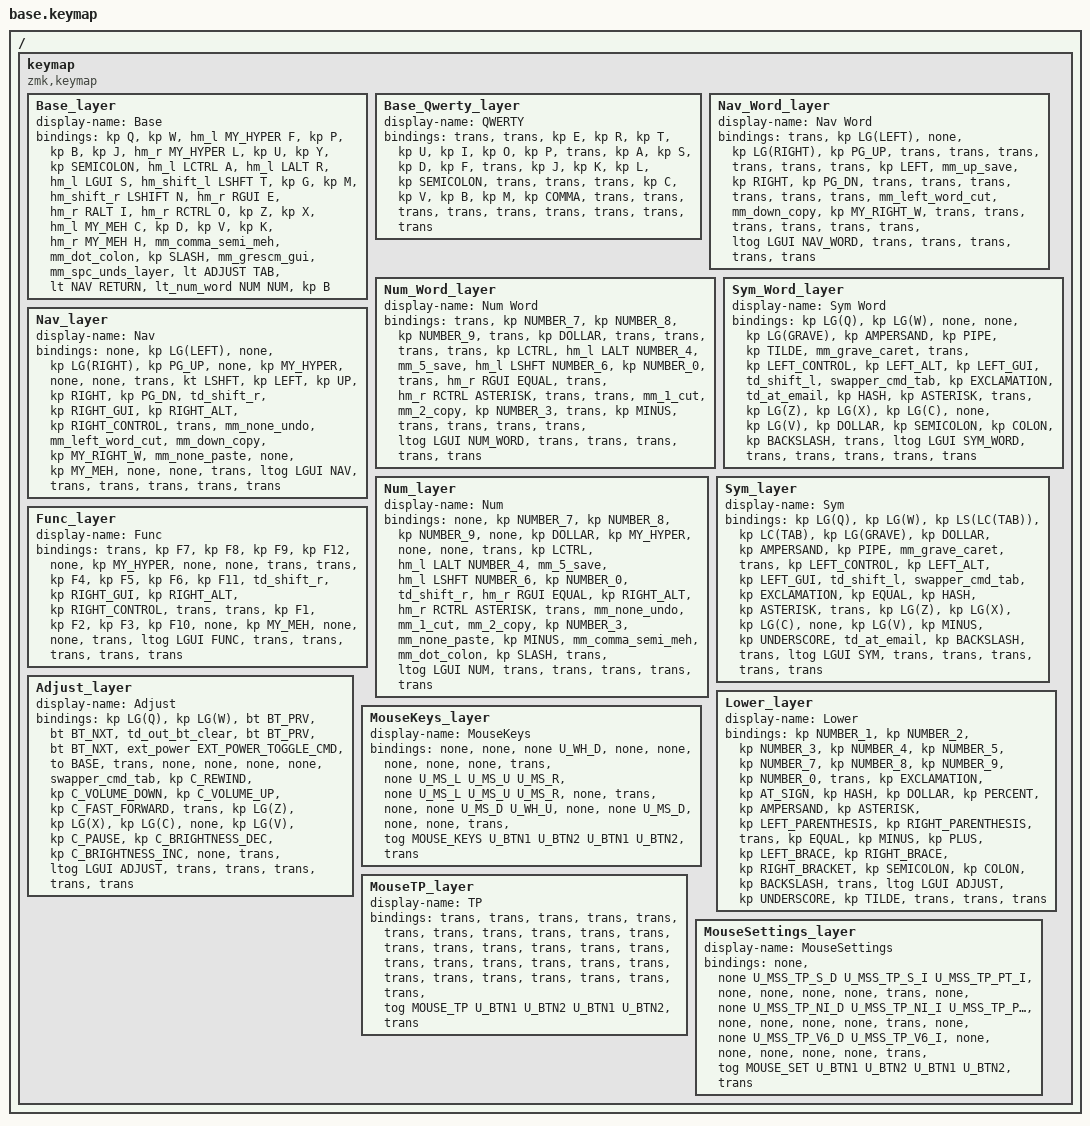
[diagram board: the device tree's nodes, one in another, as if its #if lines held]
/*
 * Copyright (c) 2020 The ZMK Contributors
 *
 * SPDX-License-Identifier: MIT
 */

// Define layer numbers
#define BASE 0
#define BASE_QWERTY 1
#define NAV_WORD 2
#define NUM_WORD 3
#define SYM_WORD 4
#define NAV 5
#define NUM 6
#define SYM 7
#define FUNC 8
#define ADJUST 9
#define LOWER 10
#define MOUSE_KEYS 11
#define MOUSE_TP 12
#define MOUSE_SET 13


// ZMK includes
#include <behaviors.dtsi>
#include <dt-bindings/zmk/keys.h>
#include <dt-bindings/zmk/bt.h>
#include <dt-bindings/zmk/rgb.h>
#include <dt-bindings/zmk/ext_power.h>

#ifdef HAS_MOUSE_KEYS
#include <dt-bindings/zmk/mouse.h>
#endif

#ifdef HAS_PS2
#include <dt-bindings/zmk/mouse_settings.h>
#endif


// Personal includes
#include "includes/custom_keycodes.dtsi"
#include "includes/settings.dtsi"
//#include "includes/settings_pd.dtsi"
#include "includes/conditional_layers.dtsi"
#include "includes/macros.dtsi"
#include "includes/combos.dtsi"
#include "includes/behaviours_homerow_mods.dtsi"
#include "includes/behaviours_mod_morph.dtsi"
#include "includes/behaviours_other.dtsi"

// Enable Mouse Keys

#ifdef HAS_MOUSE_KEYS
#include "includes/mouse_keys.dtsi"
#endif


/ {

  keymap {
    compatible = "zmk,keymap";

    Base_layer {
      display-name = "Base";
      bindings = <
// ┬────────────────────────┬────────────────────────┬────────────────────────┬────────────────────────┬────────────────────────╮    ┬────────────────────────┬────────────────────────┬───────────────────────┬─────────────────────
     &kp Q                    &kp W                    &hm_l MY_HYPER F         &kp P                    &kp B                         &kp J                    &hm_r MY_HYPER L         &kp U                    &kp Y         &kp SEMICOLON
// ┼────────────────────────┼────────────────────────┼────────────────────────┼────────────────────────┼────────────────────────┤    ┼────────────────────────┼────────────────────────┼───────────────────────┼────────────────────────┼────────────────────────┤
     &hm_l LCTRL A            &hm_l LALT R             &hm_l LGUI S             &hm_shift_l LSHFT T      &kp G                         &kp M                   &hm_shift_r LSHIFT N      &hm_r RGUI E             &hm_r RALT I             &hm_r RCTRL O
// ┼────────────────────────┼────────────────────────┼────────────────────────┼────────────────────────┼────────────────────────┤    ┼────────────────────────┼────────────────────────┼───────────────────────┼────────────────────────┼────────────────────────┤
     &kp Z                    &kp X                    &hm_l MY_MEH C           &kp D                    &kp V                         &kp K                   &hm_r MY_MEH H           &mm_comma_semi_meh       &mm_dot_colon            &kp SLASH
// ╰────────────────────────┴────────────────────────┴────────────────────────┴────────────────────────┼────────────────────────┼    ┼────────────────────────┼────────────────────────┼───────────────────────┼────────────────────────┼────────────────────────╯
                                                       &mm_grescm_gui           &mm_spc_unds_layer       &lt ADJUST TAB                &lt NAV RETURN           &lt_num_word NUM NUM        &kp B
//                                                   ╰────────────────────────┴────────────────────────┴────────────────────────╯    ╰────────────────────────┴────────────────────────┴────────────────────────╯

      >;
     //  sensor-bindings = <&inc_dec_kp C_VOL_DN C_VOL_UP &inc_dec_kp C_PREV C_NEXT>;
    };

    Base_Qwerty_layer {
      display-name = "QWERTY";
      bindings = <
// ┬────────────────────────┬────────────────────────┬────────────────────────┬────────────────────────┬────────────────────────╮    ┬────────────────────────┬────────────────────────┬────────────────────────┬────────────────────────┬────────────────────────╮
     &trans                   &trans                   &kp E                    &kp R                    &kp T                         &kp U                    &kp I                    &kp O                    &kp P                     &trans
// ┼────────────────────────┼────────────────────────┼────────────────────────┼────────────────────────┼────────────────────────┤    ┼────────────────────────┼────────────────────────┼────────────────────────┼────────────────────────┼────────────────────────┤
     &kp A                    &kp S                    &kp D                    &kp F                    &trans                        &kp J                    &kp K                    &kp L                    &kp SEMICOLON             &trans
// ┼────────────────────────┼────────────────────────┼────────────────────────┼────────────────────────┼────────────────────────┤    ┼────────────────────────┼────────────────────────┼────────────────────────┼────────────────────────┼────────────────────────┤
     &trans                   &trans                   &kp C                    &kp V                    &kp B                         &kp M                    &kp COMMA                &trans                   &trans                    &trans
// ┴────────────────────────┴────────────────────────┴────────────────────────┼────────────────────────┼────────────────────────┤    ┼────────────────────────┼────────────────────────┼────────────────────────┴────────────────────────┼────────────────────────╯
                                                       &trans                   &trans                   &trans                        &trans                   &trans        &trans

//                                                   ╰────────────────────────┴────────────────────────┴────────────────────────╯    ┴────────────────────────┴────────────────────────╯
      >;
    };

    Nav_Word_layer {
      display-name = "Nav Word";
      bindings = <
// ┬────────────────────────┬────────────────────────┬────────────────────────┬────────────────────────┬────────────────────────╮    ┬────────────────────────┬────────────────────────┬────────────────────────┬────────────────────────┬────────────────────────╮
     &trans                   &kp LG(LEFT)             &none                    &kp LG(RIGHT)            &kp PG_UP                     &trans                   &trans                   &trans                   &trans                    &trans
// ┼────────────────────────┼────────────────────────┼────────────────────────┼────────────────────────┼────────────────────────┤    ┼────────────────────────┼────────────────────────┼────────────────────────┼────────────────────────┼────────────────────────┤
     &trans                   &kp LEFT                 &mm_up_save              &kp RIGHT                &kp PG_DN                     &trans                   &trans                   &trans                   &trans                    &trans
// ┼────────────────────────┼────────────────────────┼────────────────────────┼────────────────────────┼────────────────────────┤    ┼────────────────────────┼────────────────────────┼────────────────────────┼────────────────────────┼────────────────────────┤
     &trans                   &mm_left_word_cut        &mm_down_copy            &kp MY_RIGHT_W           &trans                        &trans                   &trans                   &trans                   &trans                    &trans
// ┴────────────────────────┴────────────────────────┴────────────────────────┼────────────────────────┼────────────────────────┤    ┼────────────────────────┼────────────────────────┼────────────────────────┴────────────────────────┼────────────────────────╯
                                                       &ltog LGUI NAV_WORD      &trans                   &trans                        &trans                   &trans        &trans

//                                                   ╰────────────────────────┴────────────────────────┴────────────────────────╯    ┴────────────────────────┴────────────────────────╯
      >;
     //  sensor-bindings = <&inc_dec_kp C_BRI_DN C_BRI_UP &inc_dec_kp LEFT RIGHT>;
    };

    Num_Word_layer {
      display-name = "Num Word";
      bindings = <
// ┬────────────────────────┬────────────────────────┬────────────────────────┬────────────────────────┬────────────────────────╮    ┬────────────────────────┬────────────────────────┬────────────────────────┬────────────────────────┬────────────────────────╮
     &trans                   &kp NUMBER_7             &kp NUMBER_8             &kp NUMBER_9             &trans                        &kp DOLLAR               &trans                   &trans                   &trans                    &trans
// ┼────────────────────────┼────────────────────────┼────────────────────────┼────────────────────────┼────────────────────────┤    ┼────────────────────────┼────────────────────────┼────────────────────────┼────────────────────────┼────────────────────────┤
     &kp LCTRL                &hm_l LALT NUMBER_4      &mm_5_save               &hm_l LSHFT NUMBER_6     &kp NUMBER_0                  &trans                   &hm_r RGUI EQUAL         &trans                   &hm_r RCTRL ASTERISK      &trans
// ┼────────────────────────┼────────────────────────┼────────────────────────┼────────────────────────┼────────────────────────┤    ┼────────────────────────┼────────────────────────┼────────────────────────┼────────────────────────┼────────────────────────┤
     &trans                   &mm_1_cut                &mm_2_copy               &kp NUMBER_3             &trans                        &kp MINUS                &trans                   &trans                   &trans                    &trans
// ┴────────────────────────┴────────────────────────┴────────────────────────┼────────────────────────┼────────────────────────┤    ┼────────────────────────┼────────────────────────┼────────────────────────┴────────────────────────┼────────────────────────╯
                                                       &ltog LGUI NUM_WORD      &trans                   &trans                        &trans                   &trans        &trans

//                                                   ╰────────────────────────┴────────────────────────┴────────────────────────╯    ┴────────────────────────┴────────────────────────╯
      >;
     //  sensor-bindings = <&inc_dec_kp C_BRI_DN C_BRI_UP &inc_dec_kp LEFT RIGHT>;
    };

    Sym_Word_layer {
      display-name = "Sym Word";
      bindings = <
// ┬────────────────────────┬────────────────────────┬────────────────────────┬────────────────────────┬────────────────────────╮    ┬────────────────────────┬────────────────────────┬────────────────────────┬────────────────────────┬────────────────────────╮
     &kp LG(Q)                &kp LG(W)                &none                    &none                    &kp LG(GRAVE)                 &kp AMPERSAND            &kp PIPE                 &kp TILDE                &mm_grave_caret           &trans
// ┼────────────────────────┼────────────────────────┼────────────────────────┼────────────────────────┼────────────────────────┤    ┼────────────────────────┼────────────────────────┼────────────────────────┼────────────────────────┼────────────────────────┤
     &kp LEFT_CONTROL         &kp LEFT_ALT             &kp LEFT_GUI             &td_shift_l              &swapper_cmd_tab              &kp EXCLAMATION          &td_at_email             &kp HASH                 &kp ASTERISK              &trans
// ┼────────────────────────┼────────────────────────┼────────────────────────┼────────────────────────┼────────────────────────┤    ┼────────────────────────┼────────────────────────┼────────────────────────┼────────────────────────┼────────────────────────┤
     &kp LG(Z)                &kp LG(X)                &kp LG(C)                &none                    &kp LG(V)                     &kp DOLLAR               &kp SEMICOLON            &kp COLON                &kp BACKSLASH             &trans
// ┴────────────────────────┴────────────────────────┴────────────────────────┼────────────────────────┼────────────────────────┤    ┼────────────────────────┼────────────────────────┼────────────────────────┴────────────────────────┼────────────────────────╯
                                                       &ltog LGUI SYM_WORD      &trans                   &trans                        &trans                   &trans        &trans

//                                                   ╰────────────────────────┴────────────────────────┴────────────────────────╯    ┴────────────────────────┴────────────────────────╯
      >;
     //  sensor-bindings = <&inc_dec_kp C_BRI_DN C_BRI_UP &inc_dec_kp LEFT RIGHT>;
    };

    Nav_layer {
      display-name = "Nav";
      bindings = <
// ┬────────────────────────┬────────────────────────┬────────────────────────┬────────────────────────┬────────────────────────╮    ┬────────────────────────┬────────────────────────┬────────────────────────┬────────────────────────┬────────────────────────╮
     &none                    &kp LG(LEFT)             &none                    &kp LG(RIGHT)            &kp PG_UP                     &none                    &kp MY_HYPER             &none                    &none                     &trans
// ┼────────────────────────┼────────────────────────┼────────────────────────┼────────────────────────┼────────────────────────┤    ┼────────────────────────┼────────────────────────┼────────────────────────┼────────────────────────┼────────────────────────┤
     &kt LSHFT                &kp LEFT                 &kp UP                   &kp RIGHT                &kp PG_DN                     &td_shift_r              &kp RIGHT_GUI            &kp RIGHT_ALT            &kp RIGHT_CONTROL         &trans
// ┼────────────────────────┼────────────────────────┼────────────────────────┼────────────────────────┼────────────────────────┤    ┼────────────────────────┼────────────────────────┼────────────────────────┼────────────────────────┼────────────────────────┤
     &mm_none_undo            &mm_left_word_cut        &mm_down_copy            &kp MY_RIGHT_W           &mm_none_paste                &none                    &kp MY_MEH               &none                    &none                     &trans
// ┴────────────────────────┴────────────────────────┴────────────────────────┼────────────────────────┼────────────────────────┤    ┼────────────────────────┼────────────────────────┼────────────────────────┴────────────────────────┼────────────────────────╯
                                                       &ltog LGUI NAV           &trans                   &trans                        &trans                   &trans        &trans

//                                                   ╰────────────────────────┴────────────────────────┴────────────────────────╯    ┴────────────────────────┴────────────────────────╯
      >;
     //  sensor-bindings = <&inc_dec_kp C_BRI_DN C_BRI_UP &inc_dec_kp LEFT RIGHT>;
    };

    Num_layer {
      display-name = "Num";
      bindings = <
// ┬────────────────────────┬────────────────────────┬────────────────────────┬────────────────────────┬────────────────────────╮    ┬────────────────────────┬────────────────────────┬────────────────────────┬────────────────────────┬────────────────────────╮
     &none                    &kp NUMBER_7             &kp NUMBER_8             &kp NUMBER_9             &none                         &kp DOLLAR               &kp MY_HYPER             &none                    &none                     &trans
// ┼────────────────────────┼────────────────────────┼────────────────────────┼────────────────────────┼────────────────────────┤    ┼────────────────────────┼────────────────────────┼────────────────────────┼────────────────────────┼────────────────────────┤
     &kp LCTRL                &hm_l LALT NUMBER_4      &mm_5_save               &hm_l LSHFT NUMBER_6     &kp NUMBER_0                  &td_shift_r              &hm_r RGUI EQUAL         &kp RIGHT_ALT            &hm_r RCTRL ASTERISK      &trans
// ┼────────────────────────┼────────────────────────┼────────────────────────┼────────────────────────┼────────────────────────┤    ┼────────────────────────┼────────────────────────┼────────────────────────┼────────────────────────┼────────────────────────┤
     &mm_none_undo            &mm_1_cut                &mm_2_copy               &kp NUMBER_3             &mm_none_paste                &kp MINUS                &mm_comma_semi_meh       &mm_dot_colon            &kp SLASH                 &trans
// ┴────────────────────────┴────────────────────────┴────────────────────────┼────────────────────────┼────────────────────────┤    ┼────────────────────────┼────────────────────────┼────────────────────────┴────────────────────────┼────────────────────────╯
                                                       &ltog LGUI NUM           &trans                   &trans                        &trans                   &trans        &trans

//                                                   ╰────────────────────────┴────────────────────────┴────────────────────────╯    ┴────────────────────────┴────────────────────────╯
      >;
     //  sensor-bindings = <&inc_dec_kp C_BRI_DN C_BRI_UP &inc_dec_kp LEFT RIGHT>;
    };

    Sym_layer {
      display-name = "Sym";
      bindings = <
// ┬────────────────────────┬────────────────────────┬────────────────────────┬────────────────────────┬────────────────────────╮    ┬────────────────────────┬────────────────────────┬────────────────────────┬────────────────────────┬────────────────────────╮
     &kp LG(Q)                &kp LG(W)                &kp LS(LC(TAB))          &kp LC(TAB)              &kp LG(GRAVE)                 &kp DOLLAR               &kp AMPERSAND            &kp PIPE                 &mm_grave_caret           &trans
// ┼────────────────────────┼────────────────────────┼────────────────────────┼────────────────────────┼────────────────────────┤    ┼────────────────────────┼────────────────────────┼────────────────────────┼────────────────────────┼────────────────────────┤
     &kp LEFT_CONTROL         &kp LEFT_ALT             &kp LEFT_GUI             &td_shift_l              &swapper_cmd_tab              &kp EXCLAMATION          &kp EQUAL                &kp HASH                 &kp ASTERISK              &trans
// ┼────────────────────────┼────────────────────────┼────────────────────────┼────────────────────────┼────────────────────────┤    ┼────────────────────────┼────────────────────────┼────────────────────────┼────────────────────────┼────────────────────────┤
     &kp LG(Z)                &kp LG(X)                &kp LG(C)                &none &kp                LG(V)                         &kp MINUS                &kp UNDERSCORE           &td_at_email             &kp BACKSLASH             &trans
// ┴────────────────────────┴────────────────────────┴────────────────────────┼────────────────────────┼────────────────────────┤    ┼────────────────────────┼────────────────────────┼────────────────────────┴────────────────────────┼────────────────────────╯
                                                       &ltog LGUI SYM           &trans                   &trans                        &trans                   &trans        &trans

//                                                   ╰────────────────────────┴────────────────────────┴────────────────────────╯    ┴────────────────────────┴────────────────────────╯
      >;
     //  sensor-bindings = <&inc_dec_kp C_BRI_DN C_BRI_UP &inc_dec_kp LEFT RIGHT>;
    };

    Func_layer {
      display-name = "Func";
      bindings = <
// ┬────────────────────────┬────────────────────────┬────────────────────────┬────────────────────────┬────────────────────────╮    ┬────────────────────────┬────────────────────────┬────────────────────────┬────────────────────────┬────────────────────────╮
     &trans                   &kp F7                   &kp F8                   &kp F9                   &kp F12                       &none                    &kp MY_HYPER             &none                    &none                     &trans
// ┼────────────────────────┼────────────────────────┼────────────────────────┼────────────────────────┼────────────────────────┤    ┼────────────────────────┼────────────────────────┼────────────────────────┼────────────────────────┼────────────────────────┤
     &trans                   &kp F4                   &kp F5                   &kp F6                   &kp F11                       &td_shift_r              &kp RIGHT_GUI            &kp RIGHT_ALT            &kp RIGHT_CONTROL         &trans
// ┼────────────────────────┼────────────────────────┼────────────────────────┼────────────────────────┼────────────────────────┤    ┼────────────────────────┼────────────────────────┼────────────────────────┼────────────────────────┼────────────────────────┤
     &trans                   &kp F1                   &kp F2                   &kp F3                   &kp F10                       &none                    &kp MY_MEH               &none                    &none                     &trans
// ┴────────────────────────┴────────────────────────┴────────────────────────┼────────────────────────┼────────────────────────┤    ┼────────────────────────┼────────────────────────┼────────────────────────┴────────────────────────┼────────────────────────╯
                                                       &ltog LGUI FUNC          &trans                   &trans                        &trans                   &trans        &trans

//                                                   ╰────────────────────────┴────────────────────────┴────────────────────────╯    ┴────────────────────────┴────────────────────────╯
      >;
     //  sensor-bindings = <&inc_dec_kp C_BRI_DN C_BRI_UP &inc_dec_kp LEFT RIGHT>;
    };

    Adjust_layer {
      display-name = "Adjust";
      bindings = <
// ┬────────────────────────┬────────────────────────┬────────────────────────┬────────────────────────┬────────────────────────╮    ┬────────────────────────┬────────────────────────┬────────────────────────┬────────────────────────┬────────────────────────╮
     &kp LG(Q)                &kp LG(W)                &bt BT_PRV               &bt BT_NXT               &td_out_bt_clear              &bt BT_PRV               &bt BT_NXT               &ext_power EXT_POWER_TOGGLE_CMD &to BASE           &trans
// ┼────────────────────────┼────────────────────────┼────────────────────────┼────────────────────────┼────────────────────────┤    ┼────────────────────────┼────────────────────────┼────────────────────────┼────────────────────────┼────────────────────────┤
     &none                    &none                    &none                    &none                    &swapper_cmd_tab              &kp C_REWIND             &kp C_VOLUME_DOWN        &kp C_VOLUME_UP          &kp C_FAST_FORWARD        &trans
// ┼────────────────────────┼────────────────────────┼────────────────────────┼────────────────────────┼────────────────────────┤    ┼────────────────────────┼────────────────────────┼────────────────────────┼────────────────────────┼────────────────────────┤
     &kp LG(Z)                &kp LG(X)                &kp LG(C)                &none                    &kp LG(V)                     &kp C_PAUSE              &kp C_BRIGHTNESS_DEC     &kp C_BRIGHTNESS_INC     &none                     &trans
// ┴────────────────────────┴────────────────────────┴────────────────────────┼────────────────────────┼────────────────────────┤    ┼────────────────────────┼────────────────────────┼────────────────────────┴────────────────────────┼────────────────────────╯
                                                       &ltog LGUI ADJUST        &trans                   &trans                        &trans                   &trans        &trans

//                                                   ╰────────────────────────┴────────────────────────┴────────────────────────╯    ┴────────────────────────┴────────────────────────╯
      >;
     //  sensor-bindings = <&inc_dec_kp C_BRI_DN C_BRI_UP &inc_dec_kp LEFT RIGHT>;
    };

    Lower_layer {
      display-name = "Lower";
      bindings = <
// ┬────────────────────────┬────────────────────────┬────────────────────────┬────────────────────────┬────────────────────────╮    ┬────────────────────────┬────────────────────────┬────────────────────────┬────────────────────────┬────────────────────────╮
     &kp NUMBER_1             &kp NUMBER_2             &kp NUMBER_3             &kp NUMBER_4             &kp NUMBER_5                  &kp NUMBER_7             &kp NUMBER_8             &kp NUMBER_9             &kp NUMBER_0              &trans
// ┼────────────────────────┼────────────────────────┼────────────────────────┼────────────────────────┼────────────────────────┤    ┼────────────────────────┼────────────────────────┼────────────────────────┼────────────────────────┼────────────────────────┤
     &kp EXCLAMATION          &kp AT_SIGN              &kp HASH                 &kp DOLLAR               &kp PERCENT                   &kp AMPERSAND            &kp ASTERISK             &kp LEFT_PARENTHESIS     &kp RIGHT_PARENTHESIS     &trans
// ┼────────────────────────┼────────────────────────┼────────────────────────┼────────────────────────┼────────────────────────┤    ┼────────────────────────┼────────────────────────┼────────────────────────┼────────────────────────┼────────────────────────┤
     &kp EQUAL                &kp MINUS                &kp PLUS                 &kp LEFT_BRACE           &kp RIGHT_BRACE               &kp RIGHT_BRACKET        &kp SEMICOLON            &kp COLON                &kp BACKSLASH             &trans
// ┴────────────────────────┴────────────────────────┴────────────────────────┼────────────────────────┼────────────────────────┤    ┼────────────────────────┼────────────────────────┼────────────────────────┴────────────────────────┼────────────────────────╯
                                                       &ltog LGUI ADJUST        &kp UNDERSCORE           &kp TILDE                      &trans                  &trans        &trans

//                                                   ╰────────────────────────┴────────────────────────┴────────────────────────╯    ┴────────────────────────┴────────────────────────╯
      >;
     //  sensor-bindings = <&inc_dec_kp C_BRI_DN C_BRI_UP &inc_dec_kp LEFT RIGHT>;
    };

#ifdef HAS_MOUSE_KEYS
    MouseKeys_layer {
      display-name = "MouseKeys";
      bindings = <
// ┬────────────────────────┬────────────────────────┬────────────────────────┬────────────────────────┬────────────────────────╮    ┬────────────────────────┬────────────────────────┬────────────────────────┬────────────────────────┬────────────────────────╮
     &none                    &none                    &none                    U_WH_D                   &none                         &none                    &none                    &none                    &none                     &trans
// ┼────────────────────────┼────────────────────────┼────────────────────────┼────────────────────────┼────────────────────────┤    ┼────────────────────────┼────────────────────────┼────────────────────────┼────────────────────────┼────────────────────────┤
     &none                    U_MS_L                   U_MS_U                   U_MS_R                   &none                         U_MS_L                   U_MS_U                   U_MS_R                   &none                     &trans
// ┼────────────────────────┼────────────────────────┼────────────────────────┼────────────────────────┼────────────────────────┤    ┼────────────────────────┼────────────────────────┼────────────────────────┼────────────────────────┼────────────────────────┤
     &none                    &none                    U_MS_D                   U_WH_U                   &none                         &none                    U_MS_D                   &none                    &none                     &trans
// ┴────────────────────────┴────────────────────────┴────────────────────────┼────────────────────────┼────────────────────────┤    ┼────────────────────────┼────────────────────────┼────────────────────────┴────────────────────────┼────────────────────────╯
                                                       &tog MOUSE_KEYS          U_BTN1                    U_BTN2                       U_BTN1                   U_BTN2        &trans

//                                                   ╰────────────────────────┴────────────────────────┴────────────────────────╯    ┴────────────────────────┴────────────────────────╯
      >;
     //  sensor-bindings = <&inc_dec_kp C_BRI_DN C_BRI_UP &inc_dec_kp LEFT RIGHT>;
    };
#endif

#ifdef HAS_PS2
    MouseTP_layer {
      display-name = "TP";
      bindings = <
// ┬────────────────────────┬────────────────────────┬────────────────────────┬────────────────────────┬────────────────────────╮    ┬────────────────────────┬────────────────────────┬────────────────────────┬────────────────────────┬────────────────────────╮
     &trans                   &trans                   &trans                   &trans                   &trans                        &trans                   &trans                   &trans                   &trans                    &trans
// ┼────────────────────────┼────────────────────────┼────────────────────────┼────────────────────────┼────────────────────────┤    ┼────────────────────────┼────────────────────────┼────────────────────────┼────────────────────────┼────────────────────────┤
     &trans                   &trans                   &trans                   &trans                   &trans                        &trans                   &trans                   &trans                   &trans                    &trans
// ┼────────────────────────┼────────────────────────┼────────────────────────┼────────────────────────┼────────────────────────┤    ┼────────────────────────┼────────────────────────┼────────────────────────┼────────────────────────┼────────────────────────┤
     &trans                   &trans                   &trans                   &trans                   &trans                        &trans                   &trans                   &trans                   &trans                    &trans
// ┴────────────────────────┴────────────────────────┴────────────────────────┼────────────────────────┼────────────────────────┤    ┼────────────────────────┼────────────────────────┼────────────────────────┴────────────────────────┼────────────────────────╯
                                                       &tog MOUSE_TP            U_BTN1                    U_BTN2                       U_BTN1                   U_BTN2        &trans

//                                                   ╰────────────────────────┴────────────────────────┴────────────────────────╯    ┴────────────────────────┴────────────────────────╯
      >;
     //  sensor-bindings = <&inc_dec_kp C_BRI_DN C_BRI_UP &inc_dec_kp LEFT RIGHT>;
    };

    MouseSettings_layer {
      display-name = "MouseSettings";
      bindings = <
// ┬────────────────────────┬────────────────────────┬────────────────────────┬────────────────────────┬────────────────────────╮    ┬────────────────────────┬────────────────────────┬────────────────────────┬────────────────────────┬────────────────────────╮
     &none                    &none                    U_MSS_TP_S_D             U_MSS_TP_S_I             U_MSS_TP_PT_I                 &none                    &none                    &none                    &none                     &trans
// ┼────────────────────────┼────────────────────────┼────────────────────────┼────────────────────────┼────────────────────────┤    ┼────────────────────────┼────────────────────────┼────────────────────────┼────────────────────────┼────────────────────────┤
     &none                    &none                    U_MSS_TP_NI_D            U_MSS_TP_NI_I            U_MSS_TP_PT_D                 &none                    &none                    &none                    &none                     &trans
// ┼────────────────────────┼────────────────────────┼────────────────────────┼────────────────────────┼────────────────────────┤    ┼────────────────────────┼────────────────────────┼────────────────────────┼────────────────────────┼────────────────────────┤
     &none                    &none                    U_MSS_TP_V6_D            U_MSS_TP_V6_I            &none                         &none                    &none                    &none                    &none                     &trans
// ┴────────────────────────┴────────────────────────┴────────────────────────┼────────────────────────┼────────────────────────┤    ┼────────────────────────┼────────────────────────┼────────────────────────┴────────────────────────┼────────────────────────╯
                                                       &tog MOUSE_SET           U_BTN1                   U_BTN2                        U_BTN1                   U_BTN2        &trans

//                                                   ╰────────────────────────┴────────────────────────┴────────────────────────╯    ┴────────────────────────┴────────────────────────╯
      >;
     //  sensor-bindings = <&inc_dec_kp C_BRI_DN C_BRI_UP &inc_dec_kp LEFT RIGHT>;
    };
#endif
  };

};
